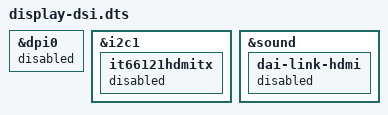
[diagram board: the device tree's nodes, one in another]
/dts-v1/;
/plugin/;

/ {
	fragment@0 {
		target = <&dpi0>;
		__overlay__ {
			status = "disabled";
		};
	};

	fragment@1 {
		target = <&i2c1>;
		__overlay__ {
			it66121hdmitx {
				status = "disabled";
			};
		};
	};

	fragment@2 {
		target = <&sound>;
		__overlay__ {
			dai-link-hdmi {
				status = "disabled";
			};
		};
	};
};
